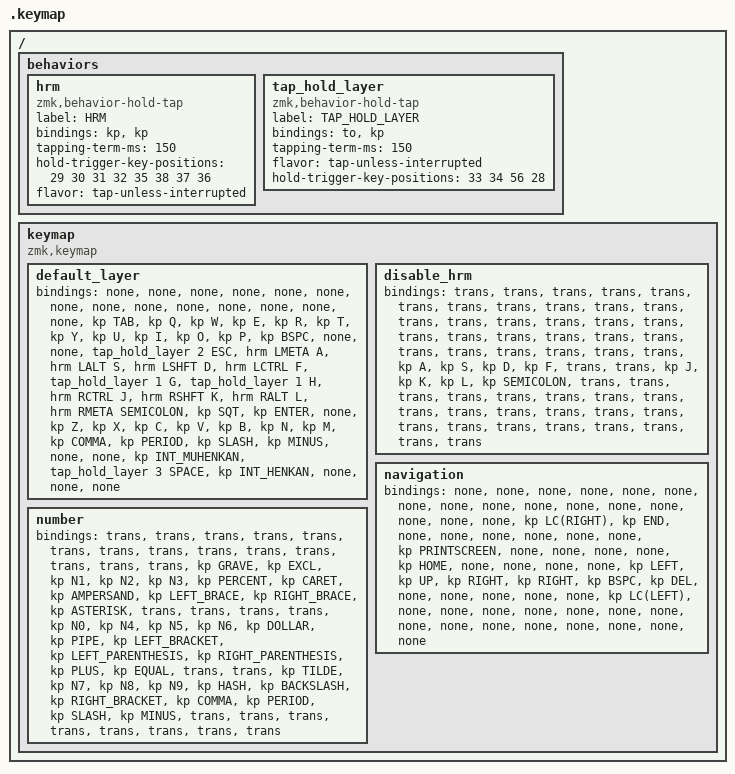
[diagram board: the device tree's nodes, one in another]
/*
 * Copyright (c) 2023 Srishtik Bhandarkar
 *
 * SPDX-License-Identifier: MIT
 */

#include <behaviors.dtsi>
#include <dt-bindings/zmk/keys.h>

/ {
    behaviors {
        hrm: hrm {
            compatible = "zmk,behavior-hold-tap";
            label = "HRM";
            bindings = <&kp>, <&kp>;

            #binding-cells = <2>;
            tapping-term-ms = <150>;
            hold-trigger-key-positions = <29 30 31 32 35 38 37 36>;
            flavor = "tap-unless-interrupted";
        };

        tap_hold_layer: tap_hold_layer {
            compatible = "zmk,behavior-hold-tap";
            label = "TAP_HOLD_LAYER";
            bindings = <&to>, <&kp>;

            #binding-cells = <2>;
            tapping-term-ms = <150>;
            flavor = "tap-unless-interrupted";
            hold-trigger-key-positions = <33 34 56 28>;
        };
    };

    keymap {
        compatible = "zmk,keymap";

        default_layer {
            // ------------------------------------------------------------------------------------------
            // | ESC |  1  |  2  |  3  |  4  |  5  |  6  |  7  |  8  |  9  |  0  |  -  |  =  |   BKSP   |
            // | TAB  |  Q  |  W  |  E  |  R  |  T  |  Y  |  U  |  I  |  O  |  P  |  [  |  ]  |   "|"   |
            // | CAPS  |  A  |  S  |  D  |  F  |  G  |  H  |  J  |  K  |  L  |  ;  |  '  |     ENTER    |
            // |  SHIFT  |  Z  |  X  |  C  |  V  |  B  |  N  |  M  |  ,  |  .  |  /  |    SHIFT  | MO(1)|
            // |  CTL  |  WIN  |  ALT  |            SPACE                      |  ALT  |  WIN   |  CTL  |
            // ------------------------------------------------------------------------------------------

            bindings = <
&none  &none  &none  &none  &none  &none  &none  &none  &none  &none  &none  &none  &none  &none  &kp TAB  &kp Q  &kp W  &kp E  &kp R  &kp T  &kp Y  &kp U  &kp I  &kp O  &kp P  &kp BSPC  &none  &none  &tap_hold_layer 2 ESC  &hrm LMETA A  &hrm LALT S  &hrm LSHFT D  &hrm LCTRL F  &tap_hold_layer 1 G  &tap_hold_layer 1 H  &hrm RCTRL J  &hrm RSHFT K  &hrm RALT L  &hrm RMETA SEMICOLON  &kp SQT  &kp ENTER  &none  &kp Z  &kp X  &kp C  &kp V  &kp B  &kp N  &kp M  &kp COMMA  &kp PERIOD  &kp SLASH  &kp MINUS  &none  &none  &kp INT_MUHENKAN  &tap_hold_layer 3 SPACE  &kp INT_HENKAN  &none  &none  &none
            >;
        };

        disable_hrm {
            bindings = <
&trans  &trans  &trans  &trans  &trans  &trans  &trans  &trans  &trans  &trans  &trans  &trans  &trans  &trans  &trans  &trans  &trans  &trans  &trans  &trans  &trans  &trans  &trans  &trans  &trans  &trans  &trans  &trans  &trans  &kp A  &kp S  &kp D  &kp F  &trans  &trans  &kp J  &kp K  &kp L  &kp SEMICOLON  &trans  &trans  &trans  &trans  &trans  &trans  &trans  &trans  &trans  &trans  &trans  &trans  &trans  &trans  &trans  &trans  &trans  &trans  &trans  &trans  &trans  &trans
            >;
        };

        navigation {
            bindings = <
&none  &none  &none  &none  &none  &none  &none  &none  &none  &none  &none  &none  &none  &none  &none  &none  &kp LC(RIGHT)  &kp END  &none  &none  &none  &none  &none  &none  &kp PRINTSCREEN  &none  &none  &none  &none  &kp HOME  &none  &none  &none  &none  &kp LEFT  &kp UP  &kp RIGHT  &kp RIGHT  &kp BSPC  &kp DEL  &none  &none  &none  &none  &none  &kp LC(LEFT)  &none  &none  &none  &none  &none  &none  &none  &none  &none  &none  &none  &none  &none  &none  &none
            >;
        };

        number {
            bindings = <
&trans  &trans  &trans  &trans  &trans  &trans  &trans  &trans  &trans  &trans  &trans  &trans  &trans  &trans  &kp GRAVE  &kp EXCL  &kp N1  &kp N2  &kp N3  &kp PERCENT  &kp CARET  &kp AMPERSAND  &kp LEFT_BRACE  &kp RIGHT_BRACE  &kp ASTERISK  &trans  &trans  &trans  &trans  &kp N0  &kp N4  &kp N5  &kp N6  &kp DOLLAR  &kp PIPE  &kp LEFT_BRACKET  &kp LEFT_PARENTHESIS  &kp RIGHT_PARENTHESIS  &kp PLUS  &kp EQUAL  &trans  &trans  &kp TILDE  &kp N7  &kp N8  &kp N9  &kp HASH  &kp BACKSLASH  &kp RIGHT_BRACKET  &kp COMMA  &kp PERIOD  &kp SLASH  &kp MINUS  &trans  &trans  &trans  &trans  &trans  &trans  &trans  &trans
            >;
        };
    };
};
